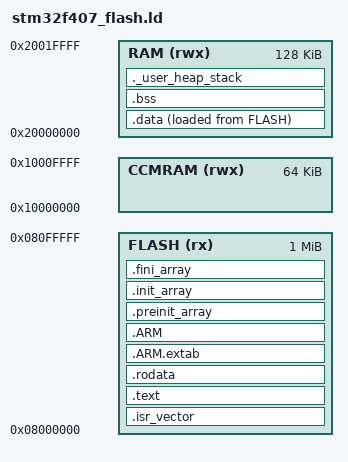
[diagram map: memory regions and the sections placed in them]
/*
 * Linker Script for STM32F407VGT6
 *
 * Flash: 1 MB (0x08000000 - 0x080FFFFF)
 * RAM:   192 KB (0x20000000 - 0x2002FFFF), of which 128 KB is SRAM1 + 64 KB CCM
 *
 * CCM RAM (0x10000000 - 0x1000FFFF) is not used in default configuration
 * to avoid DMA compatibility issues.
 */

MEMORY
{
    FLASH  (rx)  : ORIGIN = 0x08000000, LENGTH = 1024K
    RAM    (rwx) : ORIGIN = 0x20000000, LENGTH = 128K
    CCMRAM (rwx) : ORIGIN = 0x10000000, LENGTH = 64K
}

_estack = ORIGIN(RAM) + LENGTH(RAM);

SECTIONS
{
    .isr_vector :
    {
        . = ALIGN(4);
        KEEP(*(.isr_vector))
        . = ALIGN(4);
    } > FLASH

    .text :
    {
        . = ALIGN(4);
        *(.text)
        *(.text*)
        *(.glue_7)
        *(.glue_7t)
        *(.eh_frame)
        KEEP(*(.init))
        KEEP(*(.fini))
        . = ALIGN(4);
        _etext = .;
    } > FLASH

    .rodata :
    {
        . = ALIGN(4);
        *(.rodata)
        *(.rodata*)
        . = ALIGN(4);
    } > FLASH

    .ARM.extab :
    {
        . = ALIGN(4);
        *(.ARM.extab* .gnu.linkonce.armextab.*)
        . = ALIGN(4);
    } > FLASH

    .ARM :
    {
        . = ALIGN(4);
        __exidx_start = .;
        *(.ARM.exidx*)
        __exidx_end = .;
        . = ALIGN(4);
    } > FLASH

    .preinit_array :
    {
        . = ALIGN(4);
        PROVIDE_HIDDEN(__preinit_array_start = .);
        KEEP(*(.preinit_array*))
        PROVIDE_HIDDEN(__preinit_array_end = .);
        . = ALIGN(4);
    } > FLASH

    .init_array :
    {
        . = ALIGN(4);
        PROVIDE_HIDDEN(__init_array_start = .);
        KEEP(*(SORT(.init_array.*)))
        KEEP(*(.init_array*))
        PROVIDE_HIDDEN(__init_array_end = .);
        . = ALIGN(4);
    } > FLASH

    .fini_array :
    {
        . = ALIGN(4);
        PROVIDE_HIDDEN(__fini_array_start = .);
        KEEP(*(SORT(.fini_array.*)))
        KEEP(*(.fini_array*))
        PROVIDE_HIDDEN(__fini_array_end = .);
        . = ALIGN(4);
    } > FLASH

    _sidata = LOADADDR(.data);

    .data :
    {
        . = ALIGN(4);
        _sdata = .;
        *(.data)
        *(.data*)
        . = ALIGN(4);
        _edata = .;
    } > RAM AT > FLASH

    . = ALIGN(4);
    .bss :
    {
        _sbss = .;
        __bss_start__ = _sbss;
        *(.bss)
        *(.bss*)
        *(COMMON)
        . = ALIGN(4);
        _ebss = .;
        __bss_end__ = _ebss;
    } > RAM

    ._user_heap_stack :
    {
        . = ALIGN(8);
        PROVIDE(end = .);
        PROVIDE(_end = .);
        . = . + 0x400; /* Minimum heap/stack guard */
        . = ALIGN(8);
    } > RAM

    /* Discard anything not explicitly mapped */
    /DISCARD/ :
    {
        libc.a(*)
        libm.a(*)
        libgcc.a(*)
    }
}
